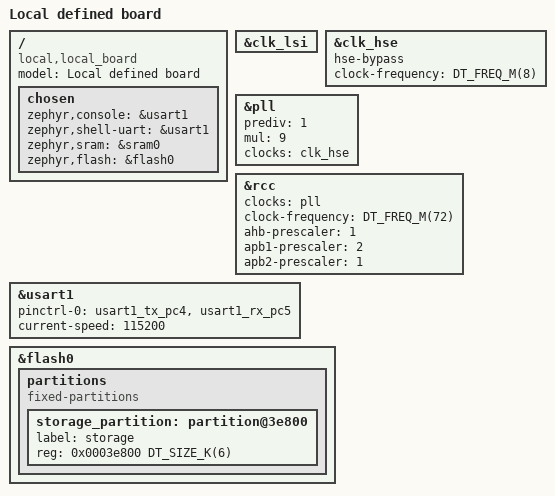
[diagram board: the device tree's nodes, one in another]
/dts-v1/;
#include <st/f3/stm32f303Xe.dtsi>
#include <st/f3/stm32f303v(b-c)tx-pinctrl.dtsi>

/ {
    model = "Local defined board";
    compatible = "local,local_board";

    chosen {
        zephyr,console = &usart1;
        zephyr,shell-uart = &usart1;
        zephyr,sram = &sram0;
        zephyr,flash = &flash0;
    };

};

&clk_lsi {
    status = "okay";
};

&clk_hse {
    hse-bypass;
    clock-frequency = <DT_FREQ_M(8)>; /* STLink 8MHz clock */
    status = "okay";
};

&pll {
    prediv = <1>;
    mul = <9>;
    clocks = <&clk_hse>;
    status = "okay";
};

&rcc {
    clocks = <&pll>;
    clock-frequency = <DT_FREQ_M(72)>;
    ahb-prescaler = <1>;
    apb1-prescaler = <2>;
    apb2-prescaler = <1>;
};

&usart1 {
    pinctrl-0 = <&usart1_tx_pc4 &usart1_rx_pc5>;
    pinctrl-names = "default";
    current-speed = <115200>;
    status = "okay";
};

&flash0 {

        partitions {
        compatible = "fixed-partitions";
        #address-cells = <1>;
        #size-cells = <1>;

        /* Set 6Kb of storage at the end of the 256Kb of flash */
        storage_partition: partition@3e800 {
            label = "storage";
            reg = <0x0003e800 DT_SIZE_K(6)>;
        };
    };
};
